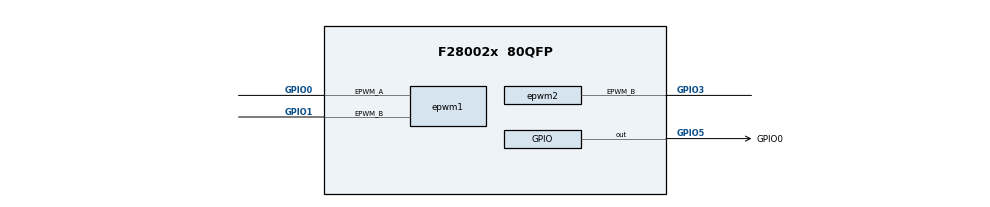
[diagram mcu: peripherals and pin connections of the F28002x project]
/**
 * @cliArgs --device "F28002x" --part "F28002x_80QFP" --package "80QFP" --context "system" --product "C2000WARE@5.04.00.00"
 * @versions {"tool":"1.21.0+3721"}
 */

/**
 * Import the modules used in this configuration.
 */
const adc     = scripting.addModule("/driverlib/adc.js", {}, false);
const adc1    = adc.addInstance();
const asysctl = scripting.addModule("/driverlib/asysctl.js");
const epwm    = scripting.addModule("/driverlib/epwm.js", {}, false);
const epwm1   = epwm.addInstance();
const epwm2   = epwm.addInstance();
const gpio    = scripting.addModule("/driverlib/gpio.js", {}, false);
const gpio1   = gpio.addInstance();

/**
 * Write custom configuration values to the imported modules.
 */
adc1.$name                       = "myADC0";
adc1.enabledSOCs                 = ["ADC_SOC_NUMBER0"];
adc1.soc0Channel                 = "ADC_CH_ADCIN3";
adc1.soc0Trigger                 = "ADC_TRIGGER_EPWM2_SOCA";
adc1.soc0InputCapacitance        = 12000;
adc1.soc0InputResistance         = 9288;
adc1.soc0UseCalculatedSampleTime = true;
adc1.adcClockPrescaler           = "ADC_CLK_DIV_5_0";
adc1.soc0SampleWindow            = 512;
adc1.interruptPulseMode          = "ADC_PULSE_END_OF_CONV";
adc1.enabledInts                 = ["ADC_INT_NUMBER1"];
adc1.enableInterrupt1            = true;
adc1.registerInterrupts          = ["1"];
adc1.adcInt1.interruptHandler    = "adcA1ISR";
adc1.adcInt1.enableInterrupt     = true;

const analog  = scripting.addModule("/driverlib/analog.js", {}, false);
const analog1 = analog.addInstance({}, false);
analog1.$name = "myANALOGPinMux0";
adc1.analog   = analog1;

asysctl.analogReference         = "INTERNAL";
asysctl.enableTemperatureSensor = true;
asysctl.analogReferenceVoltage  = "1P65";

epwm1.$name                                                      = "myEPWM1";
epwm1.epwmTimebase_counterMode                                   = "EPWM_COUNTER_MODE_UP_DOWN";
epwm1.epwmCounterCompare_cmpB                                    = 1950;
epwm1.epwmActionQualifier_EPWM_AQ_OUTPUT_A_ON_TIMEBASE_UP_CMPA   = "EPWM_AQ_OUTPUT_HIGH";
epwm1.epwmActionQualifier_EPWM_AQ_OUTPUT_A_ON_TIMEBASE_DOWN_CMPA = "EPWM_AQ_OUTPUT_LOW";
epwm1.epwmActionQualifier_EPWM_AQ_OUTPUT_B_ON_TIMEBASE_UP_CMPB   = "EPWM_AQ_OUTPUT_HIGH";
epwm1.epwmActionQualifier_EPWM_AQ_OUTPUT_B_ON_TIMEBASE_DOWN_CMPB = "EPWM_AQ_OUTPUT_LOW";
epwm1.epwmEventTrigger_enableInterrupt                           = true;
epwm1.epwmEventTrigger_interruptSource                           = "EPWM_INT_TBCTR_ZERO";
epwm1.epwmEventTrigger_interruptEventCount                       = "3";
epwm1.epwmTimebase_period                                        = 62500;
epwm1.epwmTimebase_hsClockDiv                                    = "EPWM_HSCLOCK_DIVIDER_4";
epwm1.epwmTimebase_clockDiv                                      = "EPWM_CLOCK_DIVIDER_4";
epwm1.epwmCounterCompare_cmpA                                    = 56025;
epwm1.epwm.$assign                                               = "EPWM1";
epwm1.epwm.epwm_aPin.$assign                                     = "GPIO0";
epwm1.epwm.epwm_bPin.$assign                                     = "GPIO1";

epwm2.$name                                             = "myEPWM0";
epwm2.epwmTimebase_hsClockDiv                           = "EPWM_HSCLOCK_DIVIDER_14";
epwm2.epwmTimebase_clockDiv                             = "EPWM_CLOCK_DIVIDER_8";
epwm2.epwmTimebase_period                               = 10714;
epwm2.epwmEventTrigger_EPWM_SOC_A_triggerEnable         = true;
epwm2.epwmEventTrigger_EPWM_SOC_A_triggerEventPrescalar = "1";
epwm2.epwmTimebase_counterMode                          = "EPWM_COUNTER_MODE_UP";
epwm2.epwm.epwm_bPin.$assign                            = "GPIO3";

gpio1.$name             = "GPIO0";
gpio1.writeInitialValue = true;
gpio1.direction         = "GPIO_DIR_MODE_OUT";
gpio1.gpioPin.$assign   = "GPIO5";

/**
 * Pinmux solution for unlocked pins/peripherals. This ensures that minor changes to the automatic solver in a future
 * version of the tool will not impact the pinmux you originally saw.  These lines can be completely deleted in order to
 * re-solve from scratch.
 */
analog1.analog.$suggestSolution                  = "ANALOG";
analog1.analog["a0/c15Pin"].$suggestSolution     = "A0/C15";
analog1.analog.a1Pin.$suggestSolution            = "A1";
analog1.analog["a10/c10Pin"].$suggestSolution    = "A10/C10";
analog1.analog["a11/c0Pin"].$suggestSolution     = "A11/C0";
analog1.analog["a12/c1Pin"].$suggestSolution     = "A12/C1";
analog1.analog["a14/c4Pin"].$suggestSolution     = "A14/C4";
analog1.analog["a15/c7Pin"].$suggestSolution     = "A15/C7";
analog1.analog["a2/c9Pin"].$suggestSolution      = "A2/C9";
analog1.analog["a3/c5/vdacPin"].$suggestSolution = "A3/C5/VDAC";
analog1.analog["a4/c14Pin"].$suggestSolution     = "A4/C14";
analog1.analog["a5/c2Pin"].$suggestSolution      = "A5/C2";
analog1.analog.a6Pin.$suggestSolution            = "A6";
analog1.analog["a7/c3Pin"].$suggestSolution      = "A7/C3";
analog1.analog["a8/c11Pin"].$suggestSolution     = "A8/C11";
analog1.analog["a9/c8Pin"].$suggestSolution      = "A9/C8";
analog1.analog.c6Pin.$suggestSolution            = "C6";
epwm2.epwm.$suggestSolution                      = "EPWM2";
epwm2.epwm.epwm_aPin.$suggestSolution            = "GPIO2";
